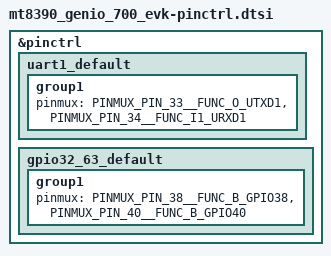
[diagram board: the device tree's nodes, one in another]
/*
 * Copyright (c) 2026 MediaTek Inc.
 *
 * SPDX-License-Identifier: Apache-2.0
 */

#include <zephyr/dt-bindings/pinctrl/mt8188-pinctrl.h>

&pinctrl {
	uart1_default: uart1_default {
		group1 {
			pinmux = <PINMUX_PIN_33__FUNC_O_UTXD1>,
				 <PINMUX_PIN_34__FUNC_I1_URXD1>;
		};
	};

	/*
	 * Every other function of these two pins is a JTAG signal, so the GPIO
	 * function has to be selected rather than relied on.  Applied by the
	 * bank that owns the pins, from its own default state.
	 */
	gpio32_63_default: gpio32_63_default {
		group1 {
			pinmux = <PINMUX_PIN_38__FUNC_B_GPIO38>,
				 <PINMUX_PIN_40__FUNC_B_GPIO40>;
		};
	};
};

/*
 * Included last so the board's own states keep the devicetree order they
 * had before this file existed: node order decides DT_FOREACH_CHILD order
 * and the child indices.
 */
#include "../common/genio-evk-pinctrl-common.dtsi"
